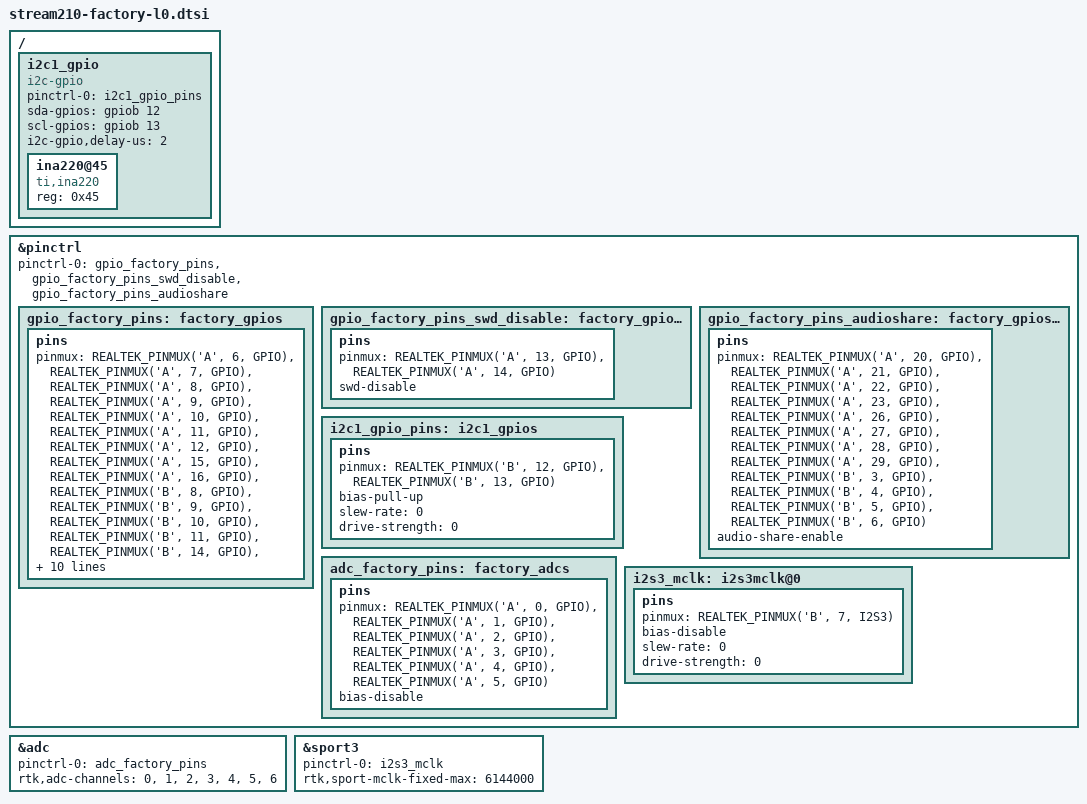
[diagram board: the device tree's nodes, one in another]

/ {
	i2c1_gpio: i2c1_gpio {
		compatible = "i2c-gpio";

		#address-cells = <1>;
		#size-cells = <0>;

		pinctrl-names = "default";
		pinctrl-0 = <&i2c1_gpio_pins>;

		sda-gpios = <&gpiob 12 (GPIO_ACTIVE_HIGH | GPIO_OPEN_DRAIN)>;
		scl-gpios = <&gpiob 13 (GPIO_ACTIVE_HIGH | GPIO_OPEN_DRAIN)>;
		i2c-gpio,delay-us = <2>;

		status = "okay";
	};
};

&pinctrl {
	pinctrl-names = "default";
	pinctrl-0 = <&gpio_factory_pins>, <&gpio_factory_pins_swd_disable>, <&gpio_factory_pins_audioshare>;

	gpio_factory_pins: factory_gpios {
		pins {
			pinmux = <REALTEK_PINMUX('A', 6, GPIO)>,
			<REALTEK_PINMUX('A', 7, GPIO)>,
			<REALTEK_PINMUX('A', 8, GPIO)>,
			<REALTEK_PINMUX('A', 9, GPIO)>,
			<REALTEK_PINMUX('A', 10, GPIO)>,
			<REALTEK_PINMUX('A', 11, GPIO)>,
			<REALTEK_PINMUX('A', 12, GPIO)>,
			<REALTEK_PINMUX('A', 15, GPIO)>,
			<REALTEK_PINMUX('A', 16, GPIO)>,
			<REALTEK_PINMUX('B', 8, GPIO)>,
			<REALTEK_PINMUX('B', 9, GPIO)>,
			<REALTEK_PINMUX('B', 10, GPIO)>,
			<REALTEK_PINMUX('B', 11, GPIO)>,
			<REALTEK_PINMUX('B', 14, GPIO)>,
			<REALTEK_PINMUX('B', 15, GPIO)>,
			<REALTEK_PINMUX('B', 16, GPIO)>,
			<REALTEK_PINMUX('B', 17, GPIO)>,
			<REALTEK_PINMUX('B', 18, GPIO)>,
			<REALTEK_PINMUX('B', 19, GPIO)>,
			<REALTEK_PINMUX('B', 20, GPIO)>,
			<REALTEK_PINMUX('B', 25, GPIO)>,
			<REALTEK_PINMUX('B', 26, GPIO)>,
			<REALTEK_PINMUX('B', 27, GPIO)>,
			<REALTEK_PINMUX('B', 29, GPIO)>;
		};
	};

	gpio_factory_pins_swd_disable: factory_gpios_swd_disable {
		pins {
			pinmux = <REALTEK_PINMUX('A', 13, GPIO)>,
			<REALTEK_PINMUX('A', 14, GPIO)>;

			swd-disable;
		};
	};

	gpio_factory_pins_audioshare: factory_gpios_audioshare {
		pins {
			pinmux = <REALTEK_PINMUX('A', 20, GPIO)>,
			<REALTEK_PINMUX('A', 21, GPIO)>,
			<REALTEK_PINMUX('A', 22, GPIO)>,
			<REALTEK_PINMUX('A', 23, GPIO)>,
			<REALTEK_PINMUX('A', 26, GPIO)>,
			<REALTEK_PINMUX('A', 27, GPIO)>,
			<REALTEK_PINMUX('A', 28, GPIO)>,
			<REALTEK_PINMUX('A', 29, GPIO)>,
			<REALTEK_PINMUX('B', 3, GPIO)>,
			<REALTEK_PINMUX('B', 4, GPIO)>,
			<REALTEK_PINMUX('B', 5, GPIO)>,
			<REALTEK_PINMUX('B', 6, GPIO)>;

			audio-share-enable;
		};
	};

	i2c1_gpio_pins: i2c1_gpios {
		pins {
			pinmux = <REALTEK_PINMUX('B', 12, GPIO)>, // I2C1_SDA
					<REALTEK_PINMUX('B', 13, GPIO)>;  // I2C1_SCL
			bias-pull-up;
			slew-rate = <0>;
			drive-strength = <0>;
		};
	};

	adc_factory_pins: factory_adcs {
		pins {
			pinmux = <REALTEK_PINMUX('A', 0, GPIO)>,
					 <REALTEK_PINMUX('A', 1, GPIO)>,
					 <REALTEK_PINMUX('A', 2, GPIO)>,
					 <REALTEK_PINMUX('A', 3, GPIO)>,
					 <REALTEK_PINMUX('A', 4, GPIO)>,
					 <REALTEK_PINMUX('A', 5, GPIO)>;
			bias-disable;
		};
	};
};

&adc {
	pinctrl-names = "default";
	pinctrl-0 = <&adc_factory_pins>;
	status = "okay";
	rtk,adc-channels = <0>, <1>, <2>, <3>, <4>, <5>, <6>;
};

&i2c1_gpio {
	ina220@45 {
		compatible = "ti,ina220";
		reg = <0x45>;
	};
};

// We will use a fixed MCLK of 6.144 MHz to calibrate the interal
// load capacitors.
&sport3 {
	pinctrl-names = "default";
	pinctrl-0 = <&i2s3_mclk>;
	rtk,sport-mclk-fixed-max = <6144000>;
};

&pinctrl {
	i2s3_mclk: i2s3mclk@0 {
		pins {
			pinmux = <REALTEK_PINMUX('B', 7, I2S3)>;
			bias-disable;
			slew-rate = <0>;
			drive-strength = <0>;
		};
	};
};
